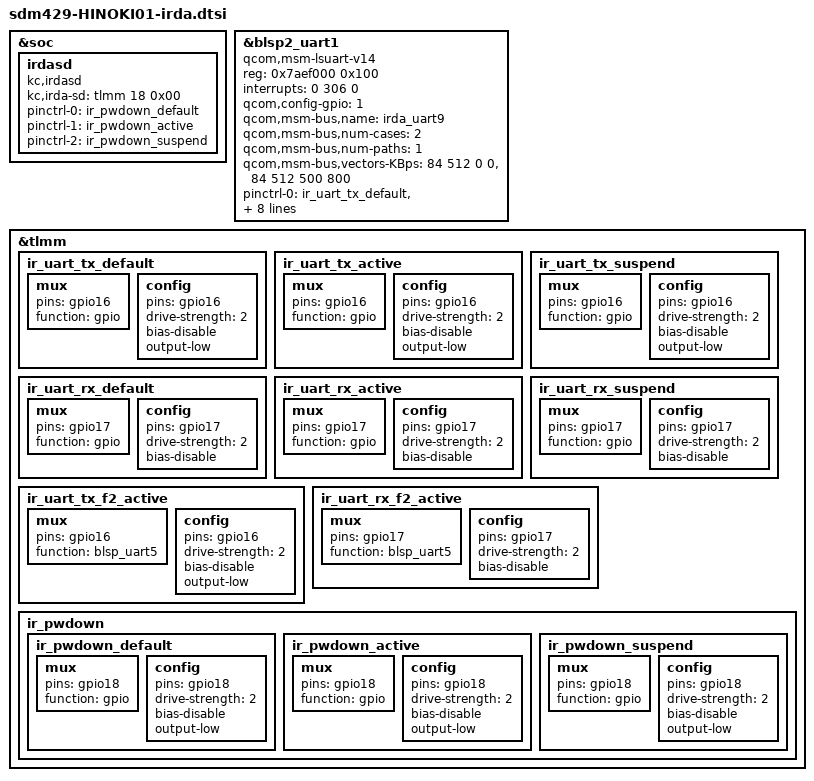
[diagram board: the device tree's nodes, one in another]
/*
 * This software is contributed or developed by KYOCERA Corporation.
 * (C) 2018 KYOCERA Corporation
 *
 * This program is free software; you can redistribute it and/or modify
 * it under the terms of the GNU General Public License version 2 and
 * only version 2 as published by the Free Software Foundation.
 *
 * This program is distributed in the hope that it will be useful,
 * but WITHOUT ANY WARRANTY; without even the implied warranty of
 * MERCHANTABILITY or FITNESS FOR A PARTICULAR PURPOSE.  See the
 * GNU General Public License for more details.
 */

#include <dt-bindings/clock/msm-clocks-8952.h>

&soc {
	irdasd {
		compatible = "kc,irdasd";
		kc,irda-sd = <&tlmm 18 0x00>;
		pinctrl-names = "ir_pwdown_default", "ir_pwdown_active",
				"ir_pwdown_suspend";
		pinctrl-0 = <&ir_pwdown_default>;
		pinctrl-1 = <&ir_pwdown_active>;
		pinctrl-2 = <&ir_pwdown_suspend>;
	};
};

&blsp2_uart1 {
	compatible = "qcom,msm-lsuart-v14";
	reg = <0x7aef000 0x100>;
	interrupts = <0 306 0>;
	status = "ok";
	qcom,config-gpio = <1>;
	qcom,msm-bus,name = "irda_uart9";
	qcom,msm-bus,num-cases = <2>;
	qcom,msm-bus,num-paths = <1>;
	qcom,msm-bus,vectors-KBps =
			<84 512 0 0>,
			<84 512 500 800>;
	pinctrl-names = "uart9_inactive", "uart9_active", "uart9_sleep";
	pinctrl-0 = <&ir_uart_tx_default &ir_uart_rx_default>;
	pinctrl-1 = <&ir_uart_tx_f2_active &ir_uart_rx_f2_active>;
	pinctrl-2 = <&ir_uart_tx_suspend &ir_uart_rx_suspend>;
	clocks = <&clock_gcc clk_gcc_blsp2_uart1_apps_clk>,
	<&clock_gcc clk_gcc_blsp2_ahb_clk>;
	clock-names = "core_clk", "iface_clk";
};

&tlmm {
	ir_uart_tx_default: ir_uart_tx_default {
		mux {
			pins = "gpio16";
			function = "gpio";
		};
		config {
			pins = "gpio16";
			drive-strength = <2>;
			bias-disable;
			output-low;
		};
	};
	ir_uart_tx_active: ir_uart_tx_active {
		mux {
			pins = "gpio16";
			function = "gpio";
		};
		config {
			pins = "gpio16";
			drive-strength = <2>;
			bias-disable;
			output-low;
		};
	};
	ir_uart_tx_suspend: ir_uart_tx_suspend {
		mux {
			pins = "gpio16";
			function = "gpio";
		};
		config {
			pins = "gpio16";
			drive-strength = <2>;
			bias-disable;
			output-low;
		};
	};

	ir_uart_rx_default: ir_uart_rx_default {
		mux {
			pins = "gpio17";
			function = "gpio";
		};
		config {
			pins = "gpio17";
			drive-strength = <2>;
			bias-disable;
		};
	};
	ir_uart_rx_active: ir_uart_rx_active {
		mux {
			pins = "gpio17";
			function = "gpio";
		};
		config {
			pins = "gpio17";
			drive-strength = <2>;
			bias-disable;
		};
	};
	ir_uart_rx_suspend: ir_uart_rx_suspend {
		mux {
			pins = "gpio17";
			function = "gpio";
		};
		config {
			pins = "gpio17";
			drive-strength = <2>;
			bias-disable;
		};
	};

	ir_uart_tx_f2_active: ir_uart_tx_f2_active {
		mux {
			pins = "gpio16";
			function = "blsp_uart5";
		};
		config {
			pins = "gpio16";
			drive-strength = <2>;
			bias-disable;
			output-low;
		};
	};

	ir_uart_rx_f2_active: ir_uart_rx_f2_active {
		mux {
			pins = "gpio17";
			function = "blsp_uart5";
		};
		config {
			pins = "gpio17";
			drive-strength = <2>;
			bias-disable;
		};
	};

	ir_pwdown {
		ir_pwdown_default: ir_pwdown_default {
			mux {
				pins = "gpio18";
				function = "gpio";
			};
			config {
				pins = "gpio18";
				drive-strength = <2>;
				bias-disable;
				output-low;
			};
		};
		ir_pwdown_active: ir_pwdown_active {
			mux {
				pins = "gpio18";
				function = "gpio";
			};
			config {
				pins = "gpio18";
				drive-strength = <2>;
				bias-disable;
				output-low;
			};
		};
		ir_pwdown_suspend: ir_pwdown_suspend {
			mux {
				pins = "gpio18";
				function = "gpio";
			};
			config {
				pins = "gpio18";
				drive-strength = <2>;
				bias-disable;
				output-low;
			};
		};
	};
};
